# V8M_Generic register map
Vendor: ARM Ltd.; Series: M; File version: 2020-08-22T15:13:24.354567-05:00
CPU: CM4 r0p0, little endian, vendor SysTick, 8 interrupt priority bits
Registers are 32-bit, read-write, no defined reset value unless marked. A register's access mark holds for its fields unless they carry their own. Offsets are from the block's base; [hi:lo] are bit positions.

## DCB — Debug Registers
Base 0xE000EDF0
0x00 DHCSR — Controls Halting debug
  [26] S_RESTART_ST — Restart sticky status
    0=PE_has_not_left_Debug_state_since_the_last_read_of_DHCSR; 1=PE_has_left_Debug_state_since_the_last_read_of_DHCSR
  [25] S_RESET_ST — Reset sticky status
    0=No_reset_since_last_DHCSR_read; 1=At_least_one_reset_since_last_DHCSR_read
  [24] S_RETIRE_ST — Retire sticky status
    0=No_instruction_retired_since_last_DHCSR_read; 1=At_least_one_instruction_retired_since_last_DHCSR_read
  [20] S_SDE — Secure debug enabled
    0=Secure_invasive_debug_prohibited; 1=Secure_invasive_debug_allowed
  [19] S_LOCKUP — Lockup status
    0=Not_locked_up; 1=Locked_up
  [18] S_SLEEP — Sleeping status
    0=Not_sleeping; 1=Sleeping
  [17] S_HALT — Halted status
    0=In_Non_debug_state; 1=In_Debug_state
  [31:16] DBGKEY — Debug key
    0xA05F=Writes_accompanied_by_this_value_update_bits_15_0; Not 0xA05F=Write_ignored
  [16] S_REGRDY — Register ready status
    0=Write_to_DCRSR_performed_but_transfer_not_yet_complete; 1=Transfer_complete_or_no_outstanding_transfer
  [5] C_SNAPSTALL — Snap stall control
    0=No_action; 1=Allow_imprecise_entry_to_Debug_state_for_example_by_forcing_any_stalled_load_or_store_instruction_to_be_abandoned
  [3] C_MASKINTS — Mask interrupts control
    0=Do_not_mask; 1=Mask_PendSV_SysTick_and_external_configurable_interrupts
  [2] C_STEP — Step control
    0=No_effect; 1=Single_step_enabled
  [1] C_HALT — Halt control
    0=Causes_the_PE_to_leave_Debug_state_if_in_Debug_state; 1=Halt_the_PE
  [0] C_DEBUGEN — Debug enable control
    0=Disabled; 1=Enabled
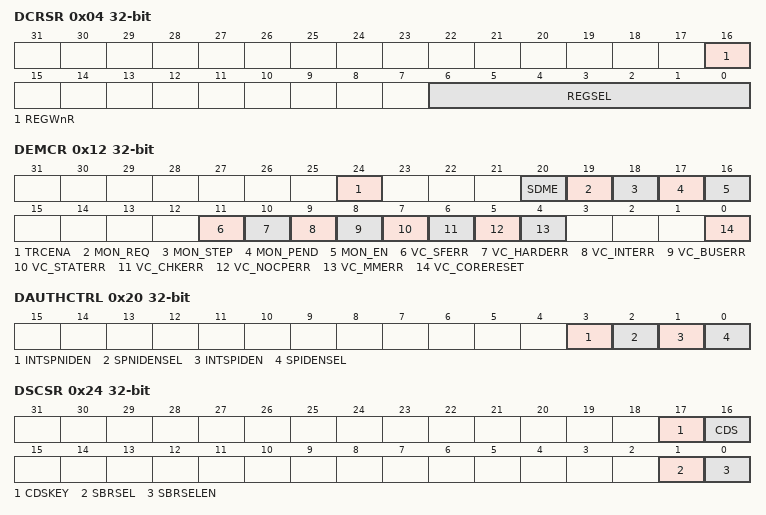
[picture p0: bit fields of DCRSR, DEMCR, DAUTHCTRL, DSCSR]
0x04 DCRSR wo — With the DCRDR, provides debug access to the general-purpose registers, special-purpose registers, and the FP extension registers. A write to the DCRSR specifies the register to transfer, whether the transfer is a read or write, and starts the transfer
  [16] REGWnR — Register write/not-read
    0=Read; 1=Write
  [6:0] REGSEL — Register selector
    0b0000000-0b0001100=General_purpose_registers_R0_R12; 13=Current_stack_pointer_SP; 14=LR; 15=DebugReturnAddress; 16=xPSR; 17=Current_state_main_stack_pointer_SP_main; 18=Current_state_process_stack_pointer_SP_process; 20=Current_state_CONTROL_7_0_FAULTMASK_7_0_BASEPRI_7_0_PRIMASK_7_0; 24=Non_secure_main_stack_pointer_MSP_NS; 25=Non_secure_process_stack_pointer_PSP_NS; 26=Secure_main_stack_pointer_MSP_S; 27=Secure_process_stack_pointer_PSP_S; 28=Secure_main_stack_limit_MSPLIM_S; 29=Secure_process_stack_limit_PSPLIM_S; 30=Non_secure_main_stack_limit_MSPLIM_NS; 31=Non_secure_process_stack_limit_PSPLIM_NS; 33=FPSCR; 34=CONTROL_7_0_FAULTMASK_7_0_BASEPRI_7_0_PRIMASK_7_0_S; 35=CONTROL_7_0_FAULTMASK_7_0_BASEPRI_7_0_PRIMASK_7_0_NS; 0b1000000-0b1011111=FP_registers_S0_S31
0x08 DCRDR — With the DCRSR, provides debug access to the general-purpose registers, special-purpose registers, and the FP Extension registers. If the Main Extension is implemented, it can also be used for message passing between an external debugger and a debug agent running on the PE
  [31:0] DBGTMP — Data temporary buffer
0x12 DEMCR ro — Manages vector catch behavior and DebugMonitor handling when debugging
  [24] TRCENA — Trace enable
    0=DWT_and_ITM_features_disabled; 1=DWT_and_ITM_features_enabled
  [20] SDME — Secure DebugMonitor enable
    0=Debug_events_prohibited_in_Secure_state_and_the_DebugMonitor_exception_targets_Non_secure_state; 1=Debug_events_allowed_in_Secure_state_and_the_DebugMonitor_exception_targets_Secure_state
  [19] MON_REQ — Monitor request
  [18] MON_STEP — Monitor step
    0=Stepping_disabled; 1=Stepping_enabled
  [17] MON_PEND — Monitor pend
    0=Clear_the_status_of_the_DebugMonitor_exception_to_not_pending; 1=Set_the_status_of_the_DebugMonitor_exception_to_pending
  [16] MON_EN — Monitor enable
    0=DebugMonitor_exception_disabled; 1=DebugMonitor_exception_enabled
  [11] VC_SFERR — Vector Catch SecureFault
    0=Halting_debug_trap_on_SecureFault_disabled; 1=Halting_debug_trap_on_SecureFault_enabled
  [10] VC_HARDERR — Vector Catch HardFault errors
    0=Halting_debug_trap_on_HardFault_disabled; 1=Halting_debug_trap_on_HardFault_enabled
  [9] VC_INTERR — Vector Catch interrupt errors
    0=Halting_debug_trap_on_faults_during_exception_entry_and_return_disabled; 1=Halting_debug_trap_on_faults_during_exception_entry_and_return_enabled
  [8] VC_BUSERR — Vector Catch BusFault errors
    0=Halting_debug_trap_on_BusFault_disabled; 1=Halting_debug_trap_on_BusFault_enabled
  [7] VC_STATERR — Vector Catch state errors
    0=Halting_debug_trap_on_UsageFault_caused_by_state_information_error_disabled; 1=Halting_debug_trap_on_UsageFault_caused_by_state_information_error_enabled
  [6] VC_CHKERR — Vector Catch check errors
    0=Halting_debug_trap_on_UsageFault_caused_by_checking_error_disabled; 1=Halting_debug_trap_on_UsageFault_caused_by_checking_error_enabled
  [5] VC_NOCPERR — Vector Catch NOCP errors
    0=Halting_debug_trap_on_UsageFault_caused_by_access_to_a_coprocessor_disabled; 1=Halting_debug_trap_on_UsageFault_caused_by_access_to_a_coprocessor_enabled
  [4] VC_MMERR — Vector Catch MemManage errors
    0=Halting_debug_trap_on_MemManage_disabled; 1=Halting_debug_trap_on_MemManage_enabled
  [0] VC_CORERESET — Vector Catch core reset
    0=Halting_debug_trap_on_reset_disabled; 1=Halting_debug_trap_on_reset_enabled
0x20 DAUTHCTRL — This register allows the IMPLEMENTATION DEFINED authentication interface to be overridden from software
  [3] INTSPNIDEN — Internal Secure non-invasive debug enable
    0=Secure_Non_invasive_debug_prohibited; 1=Secure_Non_invasive_debug_allowed
  [2] SPNIDENSEL — Secure non-invasive debug enable select
    0=Secure_non_invasive_debug_controlled_by_the_IMPLEMENTATION_DEFINED_external_authentication_interface; 1=Secure_non_invasive_debug_controlled_by_DAUTHCTRL
  [1] INTSPIDEN — Internal Secure invasive debug enable
    0=Secure_halting_and_self_hosted_debug_prohibited; 1=Secure_halting_and_self_hosted_debug_allowed
  [0] SPIDENSEL — Secure invasive debug enable select
    0=Secure_halting_and_self_hosted_debug_controlled_by_the_IMPLEMENTATION_DEFINED_external_authentication_interface; 1=Secure_halting_and_self_hosted_debug_controlled_by_DAUTHCTRL
0x24 DSCSR ro — Provides control and status information for Secure debug
  [17] CDSKEY — CDS write-enable key
    0=Concurrent_write_to_CDS_not_ignored; 1=Concurrent_write_to_CDS_ignored
  [16] CDS — Current domain Secure
    0=PE_is_in_Non_secure_state; 1=PE_is_in_Secure_state
  [1] SBRSEL — Secure Banked register select
    0=Selects_the_Non_secure_versions; 1=Selects_the_Secure_versions
  [0] SBRSELEN — Secure Banked register select enable
    0=The_current_Security_state_of_the_PE_determines_which_memory_mapped_Banked_registers_are_accessed_by_the_debugger; 1=DSCSR
